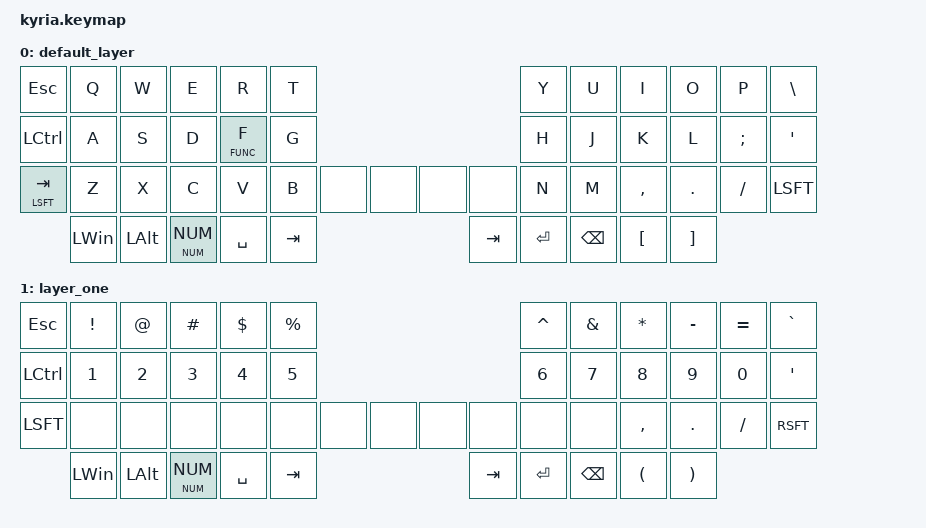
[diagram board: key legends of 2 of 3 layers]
/*
 * Copyright (c) 2020 The ZMK Contributors
 *
 * SPDX-License-Identifier: MIT
 */

#include <behaviors.dtsi>
#include <dt-bindings/zmk/keys.h>
#include <dt-bindings/zmk/bt.h>

#define DEFAULT 0
#define NUM     1
#define FUNC    2

#define NONE 0
#define BT(n) BT_SEL n

/ {
  behaviors {
      lm: number_mods {
          compatible = "zmk,behavior-hold-tap";
          label = "NUMBER_MODS";
          #binding-cells = <2>;
          tapping-term-ms = <150>;
          quick_tap_ms = <0>;
          flavor = "tap-preferred";
          bindings = <&mo>, <&sl>;
      };
  };

	keymap {
		compatible = "zmk,keymap";

		default_layer {
// -----------------------------------------------------------------------------------------------------------------------------------------------------------
// |  ESC  |  Q  |  W  |  E   |  R   |  T   |                                                  |  Y   |  U    |  I    |  O   |   P   |   \   |
// |  CTRL |  A  |  S  |  D   | F/L2 |  G   |                                                  |  H   |  J    |  K    |  L   |   ;   |   '   |
// | SHIFT |  Z  |  X  |  C   |  V   |  B   |         |         |              |       |       |  N   |  M    |  ,    |  .   |   /   | SHIFT |
//                     | WIN  | ALT  | L1   |  SPACE  |   TAB   |              |  TAB  |  RET  | DEL  |  {[   |  }]   |
			bindings = <
	&kp ESC      &kp Q &kp W &kp E &kp R &kp T                                              &kp Y &kp U &kp I    &kp O   &kp P    &kp BSLH
	&kp LCTRL    &kp A &kp S &kp D &lt FUNC F &kp G                                         &kp H &kp J &kp K    &kp L   &kp SEMI &kp QUOT
	&mt LSFT TAB &kp Z &kp X &kp C &kp V &kp B       &none   &none          &none   &none   &kp N &kp M &kp CMMA &kp DOT &kp FSLH &kp LSFT
	             &kp LWIN &kp LALT &lm NUM NUM       &kp SPC &kp TAB        &kp TAB &kp RET &kp BSPC &kp LBKT &kp RBKT
			>;

			// sensor-bindings = <&inc_dec_kp M_VOLU M_VOLD &inc_dec_kp PGUP PGDN>;
		};

		layer_one {
// -----------------------------------------------------------------------------------------------------------------------------------------------------------
// |  ESC  |  !  |  @  |  #   |  $   |  %   |                                                       |  ^   |  &    |  *    |  -/_  |   =/+ | `/~   |
// |  CTRL |  1  |  2  |  3   |  4   |  5   |                                                       |  6   |  7    |  8    |  9    |   0   |   '   |
// | SHIFT |     |     |      |      |      |         |         |                   |       |       |      |       |  ,    |  .    |   /   | SHIFT |
//                     | GUI  | DEL  | RET  |  SPACE  |   TAB   |                   |  TAB  |  RET  | DEL  |  (    |  )    |
			bindings = <

	&kp ESC   &kp EXCL &kp AT &kp HASH &kp DLLR &kp PRCNT                                        &kp CARET &kp AMPS &kp ASTRK &kp MINUS &kp EQUAL &kp GRAVE
	&kp LCTRL &kp N1   &kp N2 &kp N3   &kp N4   &kp N5                                           &kp N6    &kp N7   &kp N8    &kp N9    &kp N0    &kp QUOT
	&kp LSFT  &none    &none  &none    &none    &none     &none   &none          &none   &none   &none     &none    &kp CMMA  &kp DOT   &kp FSLH  &kp RSFT
	          &kp LWIN &kp LALT &lm NUM NUM               &kp SPC &kp TAB        &kp TAB &kp RET &kp BSPC &kp LPAR &kp RPAR
			>;

			// sensor-bindings = <&inc_dec_kp M_VOLU M_VOLD &inc_dec_kp PGUP PGDN>;
		};

    layer_two {
// ---------------------------------------------------------------------------------------------------------------------------------------------------------------
// |  ESC  |  F1 |  F2 |  F3  |  F4  |  F5  |                                                           |  F6  |  F7   |  F8   |  F9   |  F10  |  F11  |
// |  CTRL |     |     |      |      |      |                                                           | LEFT | DOWN  |  UP   | RIGHT |       |  F12  |
// | SHIFT |     |     |      |      |      |         |         |                       |       |       |      |       |  ,    | .     | /     | SHIFT |
//                     | GUI  | DEL  | RET  |  SPACE  |   TAB   |                       |  TAB  |  RET  | DEL  |  (    |  )    | 
			bindings = <
	&bt BT_CLR &kp F1    &kp F2    &kp F3    &kp F4     &kp F5                                      &kp F6   &kp F7    &kp F8    &kp F9    &kp F10  &kp F11
	&kp LCTRL  &bt BT(0) &bt BT(1) &bt BT(2) &lt FUNC F &none                                       &kp LEFT &kp DOWN  &kp UP    &kp RIGHT &none    &kp F12
	&kp LSFT   &none     &none     &none     &none            &none   &none         &none   &none   &none    &none     &kp CMMA  &kp DOT   &kp FSLH &kp RSFT
	           &kp LWIN &kp LALT &lm NUM NUM                  &kp SPC &kp TAB       &kp TAB &kp RET &kp BSPC &kp LPAR &kp RPAR
			>;

			// sensor-bindings = <&inc_dec_kp M_VOLU M_VOLD &inc_dec_kp PGUP PGDN>;
		};
	};
};
